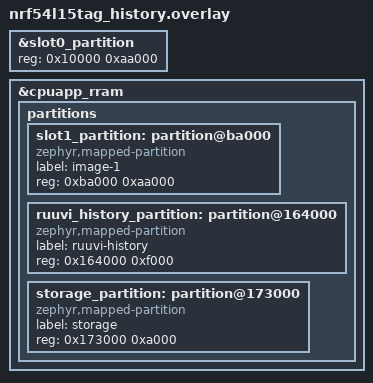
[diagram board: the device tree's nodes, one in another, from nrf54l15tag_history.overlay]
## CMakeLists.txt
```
cmake_minimum_required(VERSION 3.20.0)

set(RUUVI_VARIANT "default" CACHE STRING "Legacy application mode")
if(RUUVI_VARIANT STREQUAL "longlife" AND NOT DEFINED CONF_FILE)
    set(CONF_FILE "${CMAKE_CURRENT_SOURCE_DIR}/longlife.conf")
endif()
find_package(Zephyr REQUIRED HINTS $ENV{ZEPHYR_BASE})
project(ruuvi_nrf54_beacon)

set(RUUVI_ENDPOINTS_DIR "${CMAKE_CURRENT_SOURCE_DIR}/../nrf52_oldsdk/src/ruuvi.endpoints.c/src")
set(RUUVI_MODE_GATT_ENABLED 1)
set(RUUVI_MODE_HISTORY_ENABLED 1)
if(RUUVI_VARIANT STREQUAL "default")
    set(RUUVI_MODE_ADV_MS 1285)
    set(RUUVI_MODE_REPEATS 2)
    set(RUUVI_MODE_LOG_S 300)
    set(RUUVI_MODE_WDT_MS 360000)
    set(RUUVI_MODE_FORMATS 2)
elseif(RUUVI_VARIANT STREQUAL "debug" OR RUUVI_VARIANT STREQUAL "test")
    set(RUUVI_MODE_ADV_MS 221)
    set(RUUVI_MODE_REPEATS 2)
    set(RUUVI_MODE_LOG_S 1)
    set(RUUVI_MODE_WDT_MS 600000)
    set(RUUVI_MODE_FORMATS 2)
elseif(RUUVI_VARIANT STREQUAL "longmem")
    set(RUUVI_MODE_ADV_MS 1285)
    set(RUUVI_MODE_REPEATS 2)
    set(RUUVI_MODE_LOG_S 1800)
    set(RUUVI_MODE_WDT_MS 360000)
    set(RUUVI_MODE_FORMATS 2)
elseif(RUUVI_VARIANT STREQUAL "longlife")
    set(RUUVI_MODE_GATT_ENABLED 0)
    set(RUUVI_MODE_HISTORY_ENABLED 0)
    set(RUUVI_MODE_ADV_MS 8995)
    set(RUUVI_MODE_REPEATS 1)
    set(RUUVI_MODE_LOG_S 300)
    set(RUUVI_MODE_WDT_MS 360000)
    set(RUUVI_MODE_FORMATS 2)
elseif(RUUVI_VARIANT STREQUAL "uuid")
    set(RUUVI_MODE_ADV_MS 1285)
    set(RUUVI_MODE_REPEATS 7)
    set(RUUVI_MODE_LOG_S 300)
    set(RUUVI_MODE_WDT_MS 360000)
    set(RUUVI_MODE_FORMATS 16)
else()
    message(FATAL_ERROR "Unknown Ruuvi variant: ${RUUVI_VARIANT}")
endif()
if(RUUVI_VARIANT STREQUAL "longlife" AND (CONFIG_BT_PERIPHERAL OR CONFIG_BT_DIS))
    message(FATAL_ERROR "Longlife requires non-connectable longlife.conf; check CONF_FILE")
endif()
set(RUUVI_ENABLED_FORMATS "${RUUVI_MODE_FORMATS}" CACHE STRING "Ruuvi format mask")
math(EXPR RUUVI_CONFIGURED_FORMATS "${RUUVI_ENABLED_FORMATS} & 23")
if(NOT RUUVI_CONFIGURED_FORMATS)
    message(FATAL_ERROR "Enable at least one implemented Ruuvi data format")
endif()
math(EXPR RUUVI_ENCRYPTED_FORMATS "${RUUVI_ENABLED_FORMATS} & 40")
if(RUUVI_ENCRYPTED_FORMATS)
    message(FATAL_ERROR "DF8/FA require provisioned keys and crypto callback wiring before enabling")
endif()

# Shared endpoint codecs do not depend on the nRF5 SDK.
target_sources(app PRIVATE
    src/main.c
    src/formats.c
    src/history.c
    src/history_codec.c
    src/history_flash.c
    src/history_settings.c
    src/log_protocol.c
    src/log_service.c
    src/sensors.c
    src/ui.c
    "${RUUVI_ENDPOINTS_DIR}/ruuvi_endpoint_3.c"
    "${RUUVI_ENDPOINTS_DIR}/ruuvi_endpoint_5.c"
    "${RUUVI_ENDPOINTS_DIR}/ruuvi_endpoint_7.c"
    "${RUUVI_ENDPOINTS_DIR}/ruuvi_endpoint_8.c"
    "${RUUVI_ENDPOINTS_DIR}/ruuvi_endpoint_c5.c"
    "${RUUVI_ENDPOINTS_DIR}/ruuvi_endpoint_fa.c"
    "${RUUVI_ENDPOINTS_DIR}/ruuvi_endpoints.c"
)
if(RUUVI_MODE_GATT_ENABLED)
    target_sources(app PRIVATE src/gatt.c)
endif()
if(CONFIG_NFC_T4T_NRFXLIB)
    target_sources(app PRIVATE src/nfc.c src/nfc_codec.c)
endif()
target_include_directories(app PRIVATE "${RUUVI_ENDPOINTS_DIR}")
target_compile_definitions(app PRIVATE
    RUUVI_ENABLED_FORMATS=${RUUVI_ENABLED_FORMATS}
    RUUVI_BLE_INTERVAL_MS=${RUUVI_MODE_ADV_MS}
    RUUVI_NUM_REPEATS=${RUUVI_MODE_REPEATS}
    RUUVI_LOG_INTERVAL_S=${RUUVI_MODE_LOG_S}
    RUUVI_WDT_TIMEOUT_MS=${RUUVI_MODE_WDT_MS}
    RUUVI_GATT_ENABLED=${RUUVI_MODE_GATT_ENABLED}
    RUUVI_HISTORY_ENABLED=${RUUVI_MODE_HISTORY_ENABLED})
```

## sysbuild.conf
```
# Opt-in --sysbuild builds only. Normal upstream Zephyr builds do not load this.
SB_CONFIG_BOOTLOADER_MCUBOOT=y
SB_CONFIG_BOOT_SIGNATURE_TYPE_ECDSA_P256=y
```

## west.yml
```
manifest:
  projects:
    - name: zephyr
      url: https://github.com/zephyrproject-rtos/zephyr
      revision: v4.4.0
      import:
        name-allowlist:
          - hal_nordic
          - cmsis
          - cmsis_6
          - mbedtls
          - tf-psa-crypto
  self:
    path: nrf54_zephyr
```

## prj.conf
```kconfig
CONFIG_BT=y
CONFIG_BT_BROADCASTER=y
CONFIG_BT_PERIPHERAL=y
CONFIG_BT_MAX_CONN=1
CONFIG_BT_EXT_ADV=y
# Legacy SDK5 does not initiate PHY updates on connection (older iOS/macOS issues).
CONFIG_BT_AUTO_PHY_PERIPHERAL_NONE=y
CONFIG_POLL=y
CONFIG_BT_DEVICE_NAME_DYNAMIC=y
CONFIG_BT_DIS=y
CONFIG_BT_DIS_PNP=n
CONFIG_BT_DIS_MANUF_NAME_STR="Ruuvi Innovations Ltd"
CONFIG_BT_DIS_MODEL_NUMBER_STR="nRF54 Zephyr demo"
CONFIG_BT_DIS_FW_REV=y
CONFIG_BT_DIS_FW_REV_STR="0.1.0-demo"
CONFIG_HWINFO=y
CONFIG_SENSOR=y
CONFIG_GPIO=y
CONFIG_USE_DT_CODE_PARTITION=y
CONFIG_WATCHDOG=y
CONFIG_PICOLIBC=y
CONFIG_LOG=y
```

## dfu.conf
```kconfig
# NCS v3.4.1, opt-in DK candidate: west build --sysbuild --extra-conf dfu.conf.
# MCUboot's default signing private key is publicly shipped: test images only.
CONFIG_NCS_SAMPLE_MCUMGR_BT_OTA_DFU=y
CONFIG_NCS_SAMPLE_MCUMGR_BT_OTA_DFU_SPEEDUP=n
CONFIG_BT_SMP=y
CONFIG_MCUMGR_TRANSPORT_BT_PERM_RW_ENCRYPT=y
CONFIG_MCUBOOT_IMGTOOL_SIGN_VERSION="0.1.0+0"
CONFIG_MAIN_STACK_SIZE=4096
CONFIG_SYSTEM_WORKQUEUE_STACK_SIZE=4096
```

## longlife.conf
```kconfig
# Selected automatically for -DRUUVI_VARIANT=longlife; no GATT or history.
CONFIG_BT=y
CONFIG_BT_BROADCASTER=y
CONFIG_BT_EXT_ADV=y
CONFIG_POLL=y
CONFIG_BT_PERIPHERAL=n
CONFIG_BT_DIS=n
CONFIG_SENSOR=y
CONFIG_GPIO=y
CONFIG_WATCHDOG=y
CONFIG_USE_DT_CODE_PARTITION=y
CONFIG_PICOLIBC=y
CONFIG_LOG=n
```

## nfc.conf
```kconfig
# NCS v3.4.1 nRF54L15 DK Type 4 Tag candidate; never enable on unverified TAG UICR.
CONFIG_NFC_T4T_NRFXLIB=y
CONFIG_POLL=y
CONFIG_HWINFO=y
CONFIG_NFC_THREAD_CALLBACK=y
CONFIG_NFC_OWN_THREAD=y
CONFIG_NFC_THREAD_STACK_SIZE=1024
```

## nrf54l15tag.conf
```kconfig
# Candidate Nordic nRF54L15 TAG sensor drivers (use with nrf54l15tag.overlay).
CONFIG_I2C=y
CONFIG_BME680=y
CONFIG_ADXL367=y
```

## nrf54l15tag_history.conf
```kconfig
# Candidate TAG history layout only; coordinate with matching MCUboot partitions.
CONFIG_FLASH=y
CONFIG_FLASH_MAP=y
CONFIG_FLASH_PAGE_LAYOUT=y
CONFIG_NVS=y
CONFIG_MAIN_STACK_SIZE=4096
CONFIG_STACK_SENTINEL=y
```

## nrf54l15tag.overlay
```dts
/* Candidate Nordic nRF54L15 TAG devicetree, not a RuuviTag pin map.
 * Aliases refer only to nodes already defined by Zephyr's Nordic TAG board.
 */
/ {
    aliases {
        env0 = &bme688;
        accel0 = &adxl367;
        led0 = &led1_green;
        led1 = &led1_red;
        led2 = &led1_blue;
        watchdog0 = &wdt31;
    };
};

&wdt31 {
    status = "okay";
};
```

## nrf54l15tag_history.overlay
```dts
/* Candidate nRF54L15 TAG cpuapp layout; MCUboot must use this same layout. */
/delete-node/ &slot1_partition;
/delete-node/ &storage_partition;

&slot0_partition {
	reg = <0x10000 0xaa000>;
};

&cpuapp_rram {
	partitions {
		slot1_partition: partition@ba000 {
			compatible = "zephyr,mapped-partition";
			label = "image-1";
			reg = <0xba000 0xaa000>;
		};

		ruuvi_history_partition: partition@164000 {
			compatible = "zephyr,mapped-partition";
			label = "ruuvi-history";
			reg = <0x164000 0xf000>;
		};

		storage_partition: partition@173000 {
			compatible = "zephyr,mapped-partition";
			label = "storage";
			reg = <0x173000 0xa000>;
		};
	};
};
```

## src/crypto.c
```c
#include "crypto.h"

#include <errno.h>
#include <string.h>

#include <psa/crypto.h>

uint32_t ruuvi_aes_encrypt(const uint8_t *cleartext, uint8_t *ciphertext,
                           size_t data_size, const uint8_t *key, size_t key_size)
{
    psa_key_attributes_t attributes = PSA_KEY_ATTRIBUTES_INIT;
    psa_key_id_t key_id = PSA_KEY_ID_NULL;
    psa_status_t status;
    psa_status_t destroy_status;
    uint8_t block[16] = {0};
    volatile uint8_t *const wipe = block;
    size_t output_size = 0;
    uint32_t result = (uint32_t)EIO;

    if (cleartext == NULL || ciphertext == NULL || key == NULL ||
        data_size != sizeof(block) || key_size != sizeof(block)) {
        return (uint32_t)EINVAL;
    }

    status = psa_crypto_init();
    if (status != PSA_SUCCESS) {
        goto done;
    }

    psa_set_key_type(&attributes, PSA_KEY_TYPE_AES);
    psa_set_key_bits(&attributes, 128);
    psa_set_key_usage_flags(&attributes, PSA_KEY_USAGE_ENCRYPT);
    psa_set_key_algorithm(&attributes, PSA_ALG_ECB_NO_PADDING);

    status = psa_import_key(&attributes, key, key_size, &key_id);
    if (status != PSA_SUCCESS) {
        goto done;
    }

    status = psa_cipher_encrypt(key_id, PSA_ALG_ECB_NO_PADDING,
                                cleartext, data_size, block, sizeof(block),
                                &output_size);
    destroy_status = psa_destroy_key(key_id);
    if (status == PSA_SUCCESS && destroy_status == PSA_SUCCESS &&
        output_size == sizeof(block)) {
        memcpy(ciphertext, block, sizeof(block));
        result = 0U;
    }

done:
    psa_reset_key_attributes(&attributes);
    for (size_t i = 0; i < sizeof(block); ++i) {
        wipe[i] = 0;
    }
    return result;
}
```

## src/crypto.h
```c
#ifndef RUUVI_CRYPTO_H
#define RUUVI_CRYPTO_H

#include "formats.h"

/* One AES-128 ECB block. Returns 0 on success, EINVAL for invalid arguments,
 * or EIO for a PSA failure. Output is unchanged on failure. The caller owns
 * key provisioning; the temporary PSA key is destroyed before success.
 */
uint32_t ruuvi_aes_encrypt(const uint8_t *cleartext, uint8_t *ciphertext,
                           size_t data_size, const uint8_t *key, size_t key_size);

#endif
```

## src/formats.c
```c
#include "formats.h"

#include "ruuvi_endpoint_3.h"
#include "ruuvi_endpoint_5.h"
#include "ruuvi_endpoint_7.h"
#include "ruuvi_endpoint_8.h"
#include "ruuvi_endpoint_c5.h"
#include "ruuvi_endpoint_fa.h"

#include <errno.h>
#include <math.h>
#include <string.h>

ruuvi_format_t ruuvi_format_next(uint32_t enabled_mask, ruuvi_format_t current)
{
    const ruuvi_format_t order[] = {
        RUUVI_FORMAT_3, RUUVI_FORMAT_5, RUUVI_FORMAT_7,
        RUUVI_FORMAT_8, RUUVI_FORMAT_C5, RUUVI_FORMAT_FA,
    };
    size_t index = (sizeof(order) / sizeof(order[0])) - 1U;

    if ((enabled_mask & RUUVI_FORMAT_ALL) == 0U) {
        return RUUVI_FORMAT_INVALID;
    }

    for (size_t i = 0; i < sizeof(order) / sizeof(order[0]); ++i) {
        if (order[i] == current) {
            index = i;
            break;
        }
    }
    for (size_t i = 0; i < sizeof(order) / sizeof(order[0]); ++i) {
        index = (index + 1U) % (sizeof(order) / sizeof(order[0]));
        if ((enabled_mask & order[index]) != 0U) {
            return order[index];
        }
    }
    return RUUVI_FORMAT_INVALID;
}

int ruuvi_format_encode(ruuvi_format_t format, const ruuvi_measurement_t *measurement,
                        const ruuvi_format_crypto_t *crypto, uint8_t *output,
                        size_t *length)
{
    size_t needed;
    uint8_t payload[RUUVI_FORMAT_MAX_LENGTH] = {0};
    re_status_t status;

    if (measurement == NULL || output == NULL || length == NULL) {
        return -EINVAL;
    }

    switch (format) {
    case RUUVI_FORMAT_3: needed = RE_3_DATA_LENGTH; break;
    case RUUVI_FORMAT_5: needed = RE_5_DATA_LENGTH; break;
    case RUUVI_FORMAT_7: needed = RE_7_DATA_LENGTH; break;
    case RUUVI_FORMAT_8: needed = RE_8_DATA_LENGTH; break;
    case RUUVI_FORMAT_C5: needed = RE_C5_DATA_LENGTH; break;
    case RUUVI_FORMAT_FA: needed = RE_FA_DATA_LENGTH; break;
    default: return -EINVAL;
    }

    if (*length < needed) {
        return -ENOSPC;
    }
    if (format == RUUVI_FORMAT_8 || format == RUUVI_FORMAT_FA) {
        if (crypto == NULL || crypto->encrypt == NULL || crypto->key == NULL) {
            return -ENOTSUP;
        }
        if (crypto->key_size != RE_8_CIPHERTEXT_LENGTH) {
            return -EINVAL;
        }
    }

    switch (format) {
    case RUUVI_FORMAT_3: {
        const re_3_data_t data = {
            .humidity_rh = measurement->humidity_rh,
            .pressure_pa = measurement->pressure_pa,
            .temperature_c = measurement->temperature_c,
            .accelerationx_g = measurement->accelerationx_g,
            .accelerationy_g = measurement->accelerationy_g,
            .accelerationz_g = measurement->accelerationz_g,
            .battery_v = measurement->battery_v,
        };
        status = re_3_encode(payload, &data, NAN);
        break;
    }
    case RUUVI_FORMAT_5: {
        const re_5_data_t data = {
            .humidity_rh = measurement->humidity_rh,
            .pressure_pa = measurement->pressure_pa,
            .temperature_c = measurement->temperature_c,
            .accelerationx_g = measurement->accelerationx_g,
            .accelerationy_g = measurement->accelerationy_g,
            .accelerationz_g = measurement->accelerationz_g,
            .battery_v = measurement->battery_v,
            .measurement_count = measurement->measurement_count % (RE_5_SEQCTR_MAX + 1U),
            .movement_count = measurement->movement_count % (RE_5_MVTCTR_MAX + 1U),
            .address = measurement->address,
            .tx_power = measurement->tx_power,
        };
        status = re_5_encode(payload, &data);
        break;
    }
    case RUUVI_FORMAT_7: {
        const re_7_data_t data = {
            .humidity_rh = measurement->humidity_rh,
            .pressure_pa = measurement->pressure_pa,
            .temperature_c = measurement->temperature_c,
            .acceleration_x_g = measurement->accelerationx_g,
            .acceleration_y_g = measurement->accelerationy_g,
            .acceleration_z_g = measurement->accelerationz_g,
            .battery_v = measurement->battery_v,
            .luminosity_lux = measurement->luminosity_lux,
            .color_temp_k = measurement->color_temp_k,
            .sequence_counter = measurement->measurement_count % (RE_7_SEQCTR_MAX + 1U),
            .motion_count = measurement->movement_count % (RE_7_MOTION_CNT_MAX + 1U),
            .motion_intensity = measurement->motion_intensity,
            .motion_detected = measurement->motion_detected,
            .presence_detected = measurement->presence_detected,
            .address = measurement->address,
        };
        status = re_7_encode(payload, &data);
        break;
    }
    case RUUVI_FORMAT_8: {
        uint8_t key[RE_8_CIPHERTEXT_LENGTH];
        const re_8_data_t data = {
            .humidity_rh = measurement->humidity_rh,
            .pressure_pa = measurement->pressure_pa,
            .temperature_c = measurement->temperature_c,
            .battery_v = measurement->battery_v,
            .message_counter = measurement->measurement_count % (RE_8_SEQCTR_MAX + 1U),
            .movement_count = measurement->movement_count % (RE_8_MVTCTR_MAX + 1U),
            .address = measurement->address,
            .tx_power = measurement->tx_power,
        };
        memcpy(key, crypto->key, sizeof(key));
        for (size_t i = 0; i < 8U; ++i) {
            key[i] ^= (uint8_t)(measurement->device_id >> (i * 8U));
        }
        status = re_8_encode(payload, &data, crypto->encrypt, key, sizeof(key));
        memset(key, 0, sizeof(key));
        break;
    }
    case RUUVI_FORMAT_C5: {
        const re_c5_data_t data = {
            .humidity_rh = measurement->humidity_rh,
            .pressure_pa = measurement->pressure_pa,
            .temperature_c = measurement->temperature_c,
            .battery_v = measurement->battery_v,
            .measurement_count = measurement->measurement_count % (RE_C5_SEQCTR_MAX + 1U),
            .movement_count = measurement->movement_count % (RE_C5_MVTCTR_MAX + 1U),
            .address = measurement->address,
            .tx_power = measurement->tx_power,
        };
        status = re_c5_encode(payload, &data);
        break;
    }
    case RUUVI_FORMAT_FA: {
        const re_fa_data_t data = {
            .humidity_rh = measurement->humidity_rh,
            .pressure_pa = measurement->pressure_pa,
            .temperature_c = measurement->temperature_c,
            .accelerationx_g = measurement->accelerationx_g,
            .accelerationy_g = measurement->accelerationy_g,
            .accelerationz_g = measurement->accelerationz_g,
            .battery_v = measurement->battery_v,
            .message_counter = measurement->measurement_count % 0xFFU,
            .address = measurement->address,
        };
        status = re_fa_encode(payload, &data, crypto->encrypt, crypto->key, crypto->key_size);
        break;
    }
    default: return -EINVAL;
    }

    if (status != RE_SUCCESS) {
        return -EIO;
    }
    memcpy(output, payload, needed);
    *length = needed;
    return 0;
}
```

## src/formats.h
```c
#ifndef RUUVI_FORMATS_H
#define RUUVI_FORMATS_H

#include <stdbool.h>
#include <stddef.h>
#include <stdint.h>

/* Values are the legacy app_dataformat_t enabled-mask bits, not wire headers. */
typedef enum {
    RUUVI_FORMAT_INVALID = 0U,
    RUUVI_FORMAT_3 = 1U << 0,
    RUUVI_FORMAT_5 = 1U << 1,
    RUUVI_FORMAT_7 = 1U << 2,
    RUUVI_FORMAT_8 = 1U << 3,
    RUUVI_FORMAT_C5 = 1U << 4,
    RUUVI_FORMAT_FA = 1U << 5,
} ruuvi_format_t;

#define RUUVI_FORMAT_ALL ((uint32_t)(RUUVI_FORMAT_3 | RUUVI_FORMAT_5 | \
                                     RUUVI_FORMAT_7 | RUUVI_FORMAT_8 | \
                                     RUUVI_FORMAT_C5 | RUUVI_FORMAT_FA))
#define RUUVI_FORMAT_MAX_LENGTH 24U

typedef struct {
    float humidity_rh;
    float pressure_pa;
    float temperature_c;
    float accelerationx_g;
    float accelerationy_g;
    float accelerationz_g;
    float battery_v;
    float luminosity_lux;
    float color_temp_k;
    uint16_t measurement_count;
    uint32_t movement_count; /* Legacy interrupt counter before format-specific modulo. */
    uint8_t motion_intensity;
    bool motion_detected;
    bool presence_detected;
    uint64_t address;  /* 48-bit BLE address, MSB first on the wire. */
    int8_t tx_power;
    uint64_t device_id; /* DF8 only: XORed into the first eight key bytes, LSB first. */
} ruuvi_measurement_t;

/* Must perform real AES-128 ECB encryption of exactly one 16-byte block.
 * Signature and zero-on-success convention match the sibling endpoint codecs.
 */
typedef uint32_t (*ruuvi_aes_encrypt_fn)(const uint8_t *cleartext,
                                         uint8_t *ciphertext,
                                         size_t data_size,
                                         const uint8_t *key,
                                         size_t key_size);

typedef struct {
    ruuvi_aes_encrypt_fn encrypt;
    const uint8_t *key; /* Caller-provisioned 16-byte key; never a built-in default. */
    size_t key_size;
} ruuvi_format_crypto_t;

/* Rotate 3 -> 5 -> 7 -> 8 -> C5 -> FA -> 3, skipping disabled bits.
 * INVALID starts at 3; an empty/unknown-only mask returns INVALID.
 * The caller owns selecting advertising UUIDs and advancing counters.
 */
ruuvi_format_t ruuvi_format_next(uint32_t enabled_mask, ruuvi_format_t current);

/* Encode a raw endpoint payload, without BLE manufacturer ID or AD headers.
 * length is input capacity and output payload length; unchanged on error.
 * The buffer is untouched on error. The caller supplies counters already
 * incremented (legacy starts at 1); each codec applies its legacy modulo.
 * Pass NAN for unavailable physical values. Crypto is only used by 8/FA:
 * no callback/key => -ENOTSUP; an invalid key size => -EINVAL.
 * DF8 derives its key by XORing device_id into the first eight supplied
 * key bytes, just as legacy ep_8_key_generate did. FA uses the key as-is.
 * A successful callback must really encrypt; this layer provides no AES or keys.
 */
int ruuvi_format_encode(ruuvi_format_t format, const ruuvi_measurement_t *measurement,
                        const ruuvi_format_crypto_t *crypto, uint8_t *output,
                        size_t *length);

#endif
```

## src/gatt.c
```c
#include "gatt.h"
#include "ruuvi_endpoints.h"

#include <errno.h>
#include <stdbool.h>
#include <string.h>

#include <zephyr/bluetooth/att.h>
#include <zephyr/bluetooth/conn.h>
#include <zephyr/bluetooth/gatt.h>
#include <zephyr/bluetooth/uuid.h>

#define RUUVI_GATT_DF5_LENGTH 18U

static K_SEM_DEFINE(password_reply_sent, 0, 1);
static K_MUTEX_DEFINE(password_lock);
static struct bt_conn *password_conn;
static uint32_t password_ticket;
static bool password_pending;
static int password_result;

static void password_reply_done(struct bt_conn *conn, void *user_data)
{
    k_mutex_lock(&password_lock, K_FOREVER);
    if (password_pending && password_conn == conn &&
        (uintptr_t)user_data == (uintptr_t)password_ticket) {
        password_result = 0;
        password_pending = false;
        password_conn = NULL;
        k_sem_give(&password_reply_sent);
    }
    k_mutex_unlock(&password_lock);
}

static void password_reply_disconnected(struct bt_conn *conn, uint8_t reason)
{
    (void)reason;
    k_mutex_lock(&password_lock, K_FOREVER);
    if (password_pending && password_conn == conn) {
        password_result = -ENOTCONN;
        password_pending = false;
        password_conn = NULL;
        k_sem_give(&password_reply_sent);
    }
    k_mutex_unlock(&password_lock);
}

BT_CONN_CB_DEFINE(ruuvi_password_connections) = {
    .disconnected = password_reply_disconnected,
};

K_MSGQ_DEFINE(ruuvi_gatt_requests, sizeof(ruuvi_gatt_request_t),
              RUUVI_GATT_REQUEST_QUEUE_LEN, 1);

static ssize_t ruuvi_nus_rx_write(struct bt_conn *conn, const struct bt_gatt_attr *attr,
                                  const void *buf, uint16_t len, uint16_t offset, uint8_t flags);

#define RUUVI_RX_PROPERTIES (BT_GATT_CHRC_WRITE | BT_GATT_CHRC_WRITE_WITHOUT_RESP)
/* Zephyr only calls the prepare callback when this bit is set; reject it there. */
#define RUUVI_RX_PERMISSIONS (BT_GATT_PERM_WRITE | BT_GATT_PERM_PREPARE_WRITE)

BT_GATT_SERVICE_DEFINE(ruuvi_nus,
    BT_GATT_PRIMARY_SERVICE(BT_UUID_DECLARE_128(
        BT_UUID_128_ENCODE(0x6e400001, 0xb5a3, 0xf393, 0xe0a9, 0xe50e24dcca9e))),
    BT_GATT_CHARACTERISTIC(BT_UUID_DECLARE_128(
                               BT_UUID_128_ENCODE(0x6e400002, 0xb5a3, 0xf393,
                                                  0xe0a9, 0xe50e24dcca9e)),
                           RUUVI_RX_PROPERTIES, RUUVI_RX_PERMISSIONS, NULL,
                           ruuvi_nus_rx_write, NULL),
    BT_GATT_CHARACTERISTIC(BT_UUID_DECLARE_128(
                               BT_UUID_128_ENCODE(0x6e400003, 0xb5a3, 0xf393,
                                                  0xe0a9, 0xe50e24dcca9e)),
                           BT_GATT_CHRC_NOTIFY, BT_GATT_PERM_NONE, NULL, NULL, NULL),
    BT_GATT_CCC(NULL, BT_GATT_PERM_READ | BT_GATT_PERM_WRITE)
);

static ssize_t ruuvi_nus_rx_write(struct bt_conn *conn, const struct bt_gatt_attr *attr,
                                  const void *buf, uint16_t len, uint16_t offset, uint8_t flags)
{
    ruuvi_gatt_request_t request;

    (void)attr;
    if ((flags & ~BT_GATT_WRITE_FLAG_CMD) != 0U) {
        return BT_GATT_ERR(BT_ATT_ERR_NOT_SUPPORTED);
    }
    if (offset != 0U) {
        return BT_GATT_ERR(BT_ATT_ERR_INVALID_OFFSET);
    }
    if (len < sizeof(request.data)) {
        return BT_GATT_ERR(BT_ATT_ERR_INVALID_ATTRIBUTE_LEN);
    }
    if (conn == NULL || !bt_gatt_is_subscribed(conn, &ruuvi_nus.attrs[4],
                                                BT_GATT_CCC_NOTIFY)) {
        return BT_GATT_ERR(BT_ATT_ERR_AUTHORIZATION);
    }

    request.conn = bt_conn_ref(conn);
    if (request.conn == NULL) {
        return BT_GATT_ERR(BT_ATT_ERR_UNLIKELY);
    }
    memcpy(request.data, buf, sizeof(request.data));
    if (k_msgq_put(&ruuvi_gatt_requests, &request, K_NO_WAIT) != 0) {
        bt_conn_unref(request.conn);
        return BT_GATT_ERR(BT_ATT_ERR_INSUFFICIENT_RESOURCES);
    }

    return len;
}

int ruuvi_gatt_request_take(ruuvi_gatt_request_t *out, k_timeout_t timeout)
{
    if (out == NULL) {
        return -EINVAL;
    }
    return k_msgq_get(&ruuvi_gatt_requests, out, timeout);
}

struct k_msgq *ruuvi_gatt_request_queue(void)
{
    return &ruuvi_gatt_requests;
}

void ruuvi_gatt_request_release(ruuvi_gatt_request_t *req)
{
    if (req != NULL && req->conn != NULL) {
        bt_conn_unref(req->conn);
        req->conn = NULL;
    }
}

int ruuvi_gatt_command_send(struct bt_conn *conn, const uint8_t data[11])
{
    struct bt_conn_info info;
    int err;

    if (conn == NULL || data == NULL) {
        return -EINVAL;
    }
    if (bt_conn_get_info(conn, &info) != 0 || info.state != BT_CONN_STATE_CONNECTED) {
        return -ENOTCONN;
    }
    if (!bt_gatt_is_subscribed(conn, &ruuvi_nus.attrs[4], BT_GATT_CCC_NOTIFY)) {
        return -EACCES;
    }

    if (data[RE_STANDARD_SOURCE_INDEX] == RE_STANDARD_DESTINATION_PASSWORD &&
        (data[RE_STANDARD_OPERATION_INDEX] == RE_STANDARD_VALUE_WRITE ||
         data[RE_STANDARD_OPERATION_INDEX] == RE_STANDARD_OP_UNAUTHORIZED)) {
        k_mutex_lock(&password_lock, K_FOREVER);
        if (password_pending) {
            k_mutex_unlock(&password_lock);
            return -EAGAIN;
        }
        k_sem_reset(&password_reply_sent);
        ++password_ticket;
        if (password_ticket == 0U) {
            ++password_ticket;
        }
        uint32_t ticket = password_ticket;
        password_conn = conn; /* Caller holds a connection reference. */
        password_result = -ETIMEDOUT;
        password_pending = true;
        k_mutex_unlock(&password_lock);

        struct bt_gatt_notify_params params = {
            .attr = &ruuvi_nus.attrs[4],
            .data = data,
            .len = 11U,
            .func = password_reply_done,
            .user_data = (void *)(uintptr_t)ticket, /* Opaque cookie, never dereferenced. */
        };
        err = bt_gatt_notify_cb(conn, &params);
        int wait_rc = 0;
        if (err == 0) {
            /* Legacy waits for TX completion before dropping the old connection. */
            wait_rc = k_sem_take(&password_reply_sent, K_MSEC(4000));
        }
        k_mutex_lock(&password_lock, K_FOREVER);
        int result = err == 0 ? (wait_rc == 0 ? password_result : -ETIMEDOUT) :
                     (err == -ENOMEM ? -EAGAIN : err);
        if (password_ticket == ticket) {
            password_pending = false;
            password_conn = NULL;
        }
        k_mutex_unlock(&password_lock);
        return result;
    }

    err = bt_gatt_notify(conn, &ruuvi_nus.attrs[4], data, 11U);
    return (err == -ENOMEM) ? -EAGAIN : err;
}

int ruuvi_gatt_notify(const uint8_t *data, size_t length)
{
    if (data == NULL) {
        return -EINVAL;
    }

    if (length > RUUVI_GATT_DF5_LENGTH) {
        length = RUUVI_GATT_DF5_LENGTH;
    }

    /* Passing NULL targets only connected peers with notifications enabled. */
    int err = bt_gatt_notify(NULL, &ruuvi_nus.attrs[4], data, (uint16_t)length);

    return (err == -ENOTCONN) ? 0 : err;
}
```

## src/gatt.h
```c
#ifndef RUUVI_GATT_H_
#define RUUVI_GATT_H_

#include <stddef.h>
#include <stdint.h>

#include <zephyr/kernel.h>

struct bt_conn;

/* Legacy RI_SCHEDULER_LENGTH is 10 events, shared across event types. */
#define RUUVI_GATT_REQUEST_QUEUE_LEN 10U

typedef struct {
    uint8_t data[11];
    struct bt_conn *conn;
} ruuvi_gatt_request_t;

/* On success, the caller owns out->conn until ruuvi_gatt_request_release().
 * Log reads need a history partition; password/unsupported-op replies do not.
 */
int ruuvi_gatt_request_take(ruuvi_gatt_request_t *out, k_timeout_t timeout);
/* Expose the queue for a combined GATT/NFC k_poll wait. */
struct k_msgq *ruuvi_gatt_request_queue(void);
void ruuvi_gatt_request_release(ruuvi_gatt_request_t *req);
/* Notify the subscribed peer with an 11-byte reply. Password replies wait
 * for the local TX-completion callback before the caller may change modes.
 */
int ruuvi_gatt_command_send(struct bt_conn *conn, const uint8_t data[11]);

/* Notify subscribed NUS TX peers with at most the first 18 DF5 bytes.
 * Returns 0 if no peer is subscribed, or a negative errno on failure.
 */
int ruuvi_gatt_notify(const uint8_t *data, size_t length);

#endif /* RUUVI_GATT_H_ */
```

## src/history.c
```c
#include "history.h"
#include "history_flash.h"

#include <errno.h>
#include <stdbool.h>
#include <string.h>

/* The backend serializes access to its own flash buffer. These two records
 * live in static RAM rather than on the stack; callers serialize history API
 * calls (including reads), just as they do for the legacy logger.
 */
static ruuvi_history_record_t pending;
static ruuvi_history_record_t read_block;
static ruuvi_history_config_t configuration;
static bool present[RUUVI_HISTORY_RECORD_SLOTS];
static uint32_t generations[RUUVI_HISTORY_RECORD_SLOTS];
static uint32_t start_times[RUUVI_HISTORY_RECORD_SLOTS];
static uint8_t order[RUUVI_HISTORY_RECORD_SLOTS];
static uint8_t count;
static uint8_t next_slot;
static uint32_t next_generation;
static uint32_t last_timestamp;
static uint32_t persisted_last_timestamp;
static bool have_last_timestamp;
static bool have_persisted_timestamp;
static bool ready;

/* Serial number arithmetic: unambiguous for active generations separated by
 * less than 2^31 writes, including UINT32_MAX -> 0. Equal generations use
 * timestamp and slot as deterministic tie breakers.
 */
static bool newer(uint32_t a, uint32_t b)
{
    return a != b && (uint32_t)(a - b) < UINT32_C(0x80000000);
}

static bool precedes(uint8_t a, uint8_t b, uint32_t newest)
{
    uint32_t age_a = newest - generations[a];
    uint32_t age_b = newest - generations[b];

    if (age_a != age_b) {
        return age_a > age_b;
    }
    if (start_times[a] != start_times[b]) {
        return start_times[a] < start_times[b];
    }
    return a < b;
}

static void rebuild_order(uint32_t newest)
{
    count = 0;
    for (uint8_t slot = 0; slot < RUUVI_HISTORY_RECORD_SLOTS; ++slot) {
        if (!present[slot]) {
            continue;
        }
        uint8_t position = count++;
        while (position > 0 && precedes(slot, order[position - 1U], newest)) {
            order[position] = order[position - 1U];
            --position;
        }
        order[position] = slot;
    }
}

int ruuvi_history_init(void)
{
    int rc;
    bool found = false;
    uint8_t newest_slot = 0;
    uint32_t newest_generation = 0;
    uint32_t newest_timestamp = 0;

    ready = false;
    memset(&pending, 0, sizeof(pending));
    memset(present, 0, sizeof(present));
    count = 0;
    next_slot = 0;
    next_generation = 0;
    have_last_timestamp = false;
    have_persisted_timestamp = false;
    configuration = (ruuvi_history_config_t) {
        .interval_s = RUUVI_HISTORY_DEFAULT_INTERVAL_S,
        .overflow = RUUVI_HISTORY_DEFAULT_OVERFLOW,
        .fields = RUUVI_HISTORY_DEFAULT_FIELDS,
    };

    rc = ruuvi_history_flash_init();
    if (rc < 0) {
        return rc;
    }
    for (uint8_t slot = 0; slot < RUUVI_HISTORY_RECORD_SLOTS; ++slot) {
        uint32_t generation;
        rc = ruuvi_history_flash_read(slot, &read_block, &generation);
        if (rc == -ENOENT) {
            continue; /* Empty, interrupted, or invalid committed record. */
        }
        if (rc < 0) {
            return rc;
        }
        present[slot] = true;
        generations[slot] = generation;
        start_times[slot] = read_block.start_timestamp_s;
        if (!found || newer(generation, newest_generation) ||
            (generation == newest_generation &&
             (read_block.end_timestamp_s > newest_timestamp ||
              (read_block.end_timestamp_s == newest_timestamp && slot > newest_slot)))) {
            found = true;
            newest_slot = slot;
            newest_generation = generation;
            newest_timestamp = read_block.end_timestamp_s;
        }
    }
    if (found) {
        next_slot = (uint8_t)((newest_slot + 1U) % RUUVI_HISTORY_RECORD_SLOTS);
        next_generation = newest_generation + 1U;
        persisted_last_timestamp = newest_timestamp;
        have_persisted_timestamp = true;
        rebuild_order(newest_generation);
        /* The interval is measured against accepted samples in this session;
         * do not infer a running clock from a stored wall-clock timestamp.
         */
    }
    ready = true;
    return 0;
}

int ruuvi_history_flush(void)
{
    int rc;

    if (!ready) {
        return -EACCES;
    }
    if (pending.num_samples == 0U) {
        return 0;
    }
    if (!configuration.overflow && present[next_slot]) {
        return -ENOSPC;
    }
    rc = ruuvi_history_flash_write(next_slot, &pending, next_generation);
    if (rc < 0) {
        return rc;
    }
    persisted_last_timestamp = pending.end_timestamp_s;
    have_persisted_timestamp = true;
    present[next_slot] = true;
    generations[next_slot] = next_generation;
    start_times[next_slot] = pending.start_timestamp_s;
    rebuild_order(next_generation);
    next_generation++;
    next_slot = (uint8_t)((next_slot + 1U) % RUUVI_HISTORY_RECORD_SLOTS);
    memset(&pending, 0, sizeof(pending));
    return 0;
}

int ruuvi_history_process(const ruuvi_history_element_t *sample)
{
    int rc;
    uint32_t timestamp;

    if (sample == NULL) {
        return -EINVAL;
    }
    if (!ready) {
        return -EACCES;
    }
    timestamp = sample->timestamp_s;
    if ((have_last_timestamp && timestamp < last_timestamp) ||
        (have_persisted_timestamp && timestamp < persisted_last_timestamp)) {
        return -EINVAL;
    }
    if (pending.num_samples == RUUVI_HISTORY_SAMPLES_PER_RECORD) {
        rc = ruuvi_history_flush();
        if (rc < 0) {
            return rc;
        }
    }
    if (have_last_timestamp && timestamp - last_timestamp < configuration.interval_s) {
        return 0;
    }
    if (pending.num_samples == RUUVI_HISTORY_SAMPLES_PER_RECORD - 1U &&
        !configuration.overflow && present[next_slot]) {
        return -ENOSPC;
    }
    if (pending.num_samples == 0U) {
        pending.start_timestamp_s = timestamp;
        pending.block_configuration = configuration;
    }
    pending.storage[pending.num_samples++] = *sample;
    pending.end_timestamp_s = timestamp;
    last_timestamp = timestamp;
    have_last_timestamp = true;
    if (pending.num_samples == RUUVI_HISTORY_SAMPLES_PER_RECORD) {
        rc = ruuvi_history_flush();
        if (rc < 0) {
            return rc; /* Full block retained in RAM for a later retry. */
        }
    }
    return 1;
}

int ruuvi_history_read(uint32_t min_timestamp_s, uint32_t index,
                       ruuvi_history_element_t *sample)
{
    if (sample == NULL) {
        return -EINVAL;
    }
    if (!ready) {
        return -EACCES;
    }
    for (uint8_t i = 0; i <= count; ++i) {
        const ruuvi_history_record_t *block;
        int rc;

        if (i == count) {
            block = &pending;
        } else {
            uint8_t slot = order[i];
            uint32_t generation;
            rc = ruuvi_history_flash_read(slot, &read_block, &generation);
            if (rc == -ENOENT || (rc == 0 && generation != generations[slot])) {
                continue; /* Slot was lost/replaced since the last scan. */
            }
            if (rc < 0) {
                return rc;
            }
            block = &read_block;
        }
        for (uint32_t j = 0; j < block->num_samples; ++j) {
            if (block->storage[j].timestamp_s >= min_timestamp_s) {
                if (index == 0U) {
                    *sample = block->storage[j];
                    return 0;
                }
                --index;
            }
        }
    }
    return -ENOENT;
}

int ruuvi_history_latest_timestamp(uint32_t *timestamp_s)
{
    if (timestamp_s == NULL) {
        return -EINVAL;
    }
    if (!ready) {
        return -EACCES;
    }
    if (pending.num_samples != 0U) {
        *timestamp_s = pending.end_timestamp_s;
        return 0;
    }
    if (count == 0U) {
        return -ENOENT;
    }

    const uint8_t slot = order[count - 1U];
    uint32_t generation;
    int rc = ruuvi_history_flash_read(slot, &read_block, &generation);
    if (rc < 0) {
        return rc;
    }
    if (generation != generations[slot]) {
        return -EIO;
    }
    *timestamp_s = read_block.end_timestamp_s;
    return 0;
}

int ruuvi_history_config_set(const ruuvi_history_config_t *config)
{
    int rc;

    if (config == NULL || config->interval_s == 0U) {
        return -EINVAL;
    }
    if (!ready) {
        return -EACCES;
    }
    if (config->interval_s == configuration.interval_s &&
        config->overflow == configuration.overflow &&
        config->fields == configuration.fields) {
        return 0;
    }
    rc = ruuvi_history_flush();
    if (rc < 0) {
        return rc;
    }
    configuration = *config;
    return 0;
}

int ruuvi_history_config_get(ruuvi_history_config_t *config)
{
    if (config == NULL) {
        return -EINVAL;
    }
    if (!ready) {
        return -EACCES;
    }
    *config = configuration;
    return 0;
}

int ruuvi_history_clear(void)
{
    int rc;

    if (!ready) {
        return -EACCES;
    }
    rc = ruuvi_history_flash_clear();
    if (rc < 0) {
        ready = false;
        return rc;
    }
    memset(present, 0, sizeof(present));
    memset(&pending, 0, sizeof(pending));
    count = 0;
    next_slot = 0;
    next_generation = 0;
    have_last_timestamp = false;
    have_persisted_timestamp = false;
    return 0;
}
```

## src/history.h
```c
#ifndef RUUVI_HISTORY_H
#define RUUVI_HISTORY_H

#include "history_codec.h"

#include <stdint.h>

/* Mount and scan committed slots without clearing them. Calling init again
 * simulates a restart: unflushed samples and RAM-only configuration are lost.
 */
int ruuvi_history_init(void);

/* Accept a caller-timestamped sample when the interval has elapsed (including
 * the first sample). Return 1 if accepted, 0 if skipped, or negative errno.
 * Accepted samples are RAM-only until a full block writes successfully or
 * flush succeeds. If an automatic full-block write fails, a negative errno
 * is returned but that last sample remains in RAM for a flush retry.
 * Timestamps must not go backwards within one session or precede the most
 * recent committed block's end timestamp after a restart.
 */
int ruuvi_history_process(const ruuvi_history_element_t *sample);

/* Persist the pending partial block. On failure it remains pending for retry. */
int ruuvi_history_flush(void);

/* Chronological, zero-based sample index at or after min_timestamp_s. Records
 * are ordered by wrap-safe generation, then timestamp for equal generations;
 * the unflushed RAM block follows committed records. -ENOENT means end of log.
 * This is not a snapshot: restart traversal after a concurrent write/clear.
 */
int ruuvi_history_read(uint32_t min_timestamp_s, uint32_t index,
                       ruuvi_history_element_t *sample);
/* Last committed or pending timestamp, in caller-defined seconds. Returns
 * -ENOENT for an empty log; unlike a full read, this scans at most one slot.
 */
int ruuvi_history_latest_timestamp(uint32_t *timestamp_s);

/* Configuration is RAM-only; it resets to defaults on init/reboot. A change
 * flushes the previous block first and does not take effect if flush fails.
 * interval_s must be nonzero. overflow=false refuses to overwrite a slot.
 */
int ruuvi_history_config_set(const ruuvi_history_config_t *config);
int ruuvi_history_config_get(ruuvi_history_config_t *config);

/* Erase the partition and discard unflushed samples. A failed clear requires
 * init before further use; flash_clear is not power-fail atomic.
 */
int ruuvi_history_clear(void);

#endif
```

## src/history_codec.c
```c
#include "history_codec.h"

#include <errno.h>
#include <float.h>
#include <limits.h>
#include <string.h>

_Static_assert(CHAR_BIT == 8 && sizeof(uint32_t) == 4 && sizeof(float) == 4 &&
               FLT_RADIX == 2 && FLT_MANT_DIG == 24 && FLT_MAX_EXP == 128,
               "history codec requires IEEE 754 binary32 and eight-bit bytes");
_Static_assert(RUUVI_HISTORY_RECORD_SIZE == 20U + 16U * RUUVI_HISTORY_SAMPLES_PER_RECORD,
               "history record size must include every legacy sample");

enum {
    START_OFFSET = 0,
    END_OFFSET = 4,
    COUNT_OFFSET = 8,
    INTERVAL_OFFSET = 12,
    OVERFLOW_OFFSET = 14,
    PADDING_OFFSET = 15,
    FIELDS_OFFSET = 16,
    ELEMENTS_OFFSET = 20,
    ELEMENT_SIZE = 16,
};

static void put_u16(uint8_t *dest, uint16_t value)
{
    dest[0] = (uint8_t)value;
    dest[1] = (uint8_t)(value >> 8);
}

static void put_u32(uint8_t *dest, uint32_t value)
{
    dest[0] = (uint8_t)value;
    dest[1] = (uint8_t)(value >> 8);
    dest[2] = (uint8_t)(value >> 16);
    dest[3] = (uint8_t)(value >> 24);
}

static uint16_t get_u16(const uint8_t *src)
{
    return (uint16_t)((uint16_t)src[0] | ((uint16_t)src[1] << 8));
}

static uint32_t get_u32(const uint8_t *src)
{
    return (uint32_t)src[0] | ((uint32_t)src[1] << 8) |
           ((uint32_t)src[2] << 16) | ((uint32_t)src[3] << 24);
}

static void put_float(uint8_t *dest, float value)
{
    uint32_t bits;
    memcpy(&bits, &value, sizeof(bits));
    put_u32(dest, bits);
}

static float get_float(const uint8_t *src)
{
    uint32_t bits = get_u32(src);
    float value;
    memcpy(&value, &bits, sizeof(value));
    return value;
}

int ruuvi_history_encode(const ruuvi_history_record_t *record, uint8_t *output,
                         size_t length)
{
    if (record == NULL || output == NULL || record->num_samples > RUUVI_HISTORY_SAMPLES_PER_RECORD) {
        return -EINVAL;
    }
    if (length != RUUVI_HISTORY_RECORD_SIZE) {
        return -EMSGSIZE;
    }

    put_u32(output + START_OFFSET, record->start_timestamp_s);
    put_u32(output + END_OFFSET, record->end_timestamp_s);
    put_u32(output + COUNT_OFFSET, record->num_samples);
    put_u16(output + INTERVAL_OFFSET, record->block_configuration.interval_s);
    output[OVERFLOW_OFFSET] = record->block_configuration.overflow ? 1U : 0U;
    output[PADDING_OFFSET] = 0U;
    put_u32(output + FIELDS_OFFSET, record->block_configuration.fields);

    for (size_t i = 0; i < RUUVI_HISTORY_SAMPLES_PER_RECORD; ++i) {
        uint8_t *element = output + ELEMENTS_OFFSET + i * ELEMENT_SIZE;
        put_u32(element, record->storage[i].timestamp_s);
        put_float(element + 4, record->storage[i].temperature_c);
        put_float(element + 8, record->storage[i].humidity_rh);
        put_float(element + 12, record->storage[i].pressure_pa);
    }
    return 0;
}

int ruuvi_history_decode(const uint8_t *input, size_t length,
                         ruuvi_history_record_t *record)
{
    if (input == NULL || record == NULL) {
        return -EINVAL;
    }
    if (length != RUUVI_HISTORY_RECORD_SIZE) {
        return -EMSGSIZE;
    }
    if (get_u32(input + COUNT_OFFSET) > RUUVI_HISTORY_SAMPLES_PER_RECORD ||
        input[OVERFLOW_OFFSET] > 1U) {
        return -EINVAL;
    }

    record->start_timestamp_s = get_u32(input + START_OFFSET);
    record->end_timestamp_s = get_u32(input + END_OFFSET);
    record->num_samples = get_u32(input + COUNT_OFFSET);
    record->block_configuration.interval_s = get_u16(input + INTERVAL_OFFSET);
    record->block_configuration.overflow = input[OVERFLOW_OFFSET] != 0U;
    record->block_configuration.fields = get_u32(input + FIELDS_OFFSET);

    for (size_t i = 0; i < RUUVI_HISTORY_SAMPLES_PER_RECORD; ++i) {
        const uint8_t *element = input + ELEMENTS_OFFSET + i * ELEMENT_SIZE;
        record->storage[i].timestamp_s = get_u32(element);
        record->storage[i].temperature_c = get_float(element + 4);
        record->storage[i].humidity_rh = get_float(element + 8);
        record->storage[i].pressure_pa = get_float(element + 12);
    }
    return 0;
}
```

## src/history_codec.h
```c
#ifndef RUUVI_HISTORY_CODEC_H
#define RUUVI_HISTORY_CODEC_H

#include <stdbool.h>
#include <stddef.h>
#include <stdint.h>

/* Legacy app_config.h: 16 flash pages, two reserved for swap/settings. */
#define RUUVI_HISTORY_RECORD_SLOTS 14U
/* Legacy app_log.h: (4096 - 96) / sizeof(app_log_element_t), 16 bytes each. */
#define RUUVI_HISTORY_SAMPLES_PER_RECORD 250U
#define RUUVI_HISTORY_RECORD_SIZE 4020U
#define RUUVI_HISTORY_DEFAULT_INTERVAL_S 300U
#define RUUVI_HISTORY_DEFAULT_OVERFLOW true
/* rd_sensor_data_fields_t is a uint32_t union, not a byte-sized enum.
 * On the legacy little-endian ARM build: humidity bit 7, pressure bit 16,
 * temperature bit 18. Keep all other bits when encoding/decoding.
 */
#define RUUVI_HISTORY_DEFAULT_FIELDS ((1U << 7) | (1U << 16) | (1U << 18))

/* Fixed-width equivalent of app_log_config_t and app_log_record_t. The wire
 * layout matches the 32-bit ARM legacy record's member offsets, not host ABI:
 * start 0, end 4, num_samples 8, interval 12, overflow 14, pad 15,
 * fields 16, storage 20; each element is timestamp + three binary32 floats.
 * All 250 elements are serialized even when num_samples is smaller.
 */
typedef struct {
    uint16_t interval_s;
    bool overflow;
    uint32_t fields;
} ruuvi_history_config_t;

typedef struct {
    uint32_t timestamp_s;
    float temperature_c;
    float humidity_rh;
    float pressure_pa;
} ruuvi_history_element_t;

typedef struct {
    uint32_t start_timestamp_s;
    uint32_t end_timestamp_s;
    uint32_t num_samples;
    ruuvi_history_config_t block_configuration;
    ruuvi_history_element_t storage[RUUVI_HISTORY_SAMPLES_PER_RECORD];
} ruuvi_history_record_t;

/* Exactly RUUVI_HISTORY_RECORD_SIZE bytes, little-endian. Return 0 on
 * success, -EINVAL for null/invalid count/overflow byte, -EMSGSIZE if
 * length differs from the fixed size. No output is changed on error.
 * This codec has no storage, flash, or rotation side effects.
 */
int ruuvi_history_encode(const ruuvi_history_record_t *record, uint8_t *output,
                         size_t length);
int ruuvi_history_decode(const uint8_t *input, size_t length,
                         ruuvi_history_record_t *record);

#endif
```

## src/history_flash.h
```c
#ifndef RUUVI_HISTORY_FLASH_H
#define RUUVI_HISTORY_FLASH_H

#include "history_codec.h"

#include <stdint.h>

/* Requires a dedicated, page-aligned ruuvi_history_partition of at least
 * 15 x 4096 bytes. Slots 0..13 contain 4020-byte payloads with a committed
 * 16-byte trailer at the end of each page; page 14 journals an overwritten
 * record. Call init before use. Only init's replay, write, and clear mutate
 * flash. Clear is not atomic across slots; a failed overwrite can leave the
 * previous committed record in the journal for reading/replay.
 */
int ruuvi_history_flash_init(void);
int ruuvi_history_flash_read(uint8_t slot, ruuvi_history_record_t *record,
                             uint32_t *generation);
int ruuvi_history_flash_write(uint8_t slot, const ruuvi_history_record_t *record,
                              uint32_t generation);
int ruuvi_history_flash_clear(void);

#endif
```
